# wl_phy_rx_11b_secure register map
Vendor: Texas Instruments
Peripheral module from a debugger description file (folder CC35X1E).
Registers are 32-bit, read-only, no defined reset value unless marked. A register's access mark holds for its fields unless they carry their own. Offsets are as the file gives them; lines under a group give offsets from that group; [hi:lo] are bit positions; {n}, {i} and the like mark numbered series; 'fields as' and 'values as' point back to an identical list; <NAME> marks a mode.

## wl_phy_rx_11b_secure
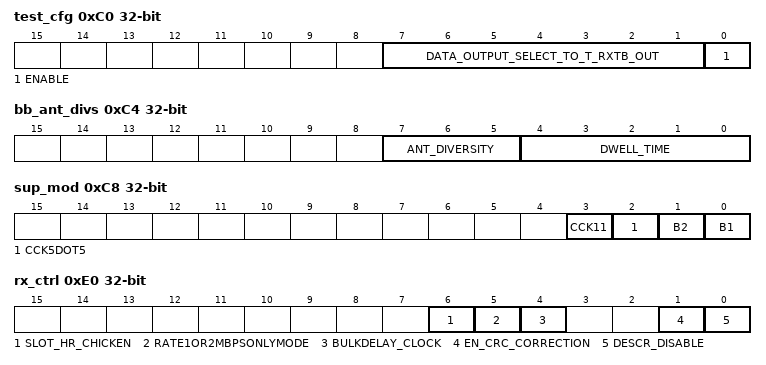
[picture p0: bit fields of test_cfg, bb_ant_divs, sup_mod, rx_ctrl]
0xC0 test_cfg access per field
  [7:1] DATA_OUTPUT_SELECT_TO_T_RXTB_OUT rw — Select data to output on t_rxtb_out
  [0] ENABLE rw — 0: disabled 1: output selected data on t_rxtb_out
0xC4 bb_ant_divs access per field — Antenna Diversity State Machine (BB_ANT_DIVS) (0x4bb1) In partial diversity, the antennas switch based on the dwell time. When barkerSync is valid at the end of a dwell time, the current antenna is declared as the one to use for the incoming packet. If the packet is later lost (or after it is completely received), the antenna switching (and searching for a new packet) will start again. In b-only full diversity, the antennas will switch based on dwell time until barkerSync is valid at the end of a dwell time. At that point the current antenna is declared the first antenna and the full diversity algorithm starts. The other full diversity modes are 11g compatible and do not switch antennas until after the rxtb block is granted control of the packet with the rxt_go_b signal. They allow control of the starting antenna when using full diversity - antenna 1 as we had in the past, and now new options to start on antenna 2 or the last antenna a packet was received on. MatanY - TODO - Can we move this register?
  [7:5] ANT_DIVERSITY rw — Ant_Diversity (802.11b-only mode, in which antennas are switched until an 11b acknowledgement. Set 0x2002 to 0x2 for 11b-only processing.) (802.11b-only mode, in which antennas are switched until an 11b acknowledgement. The last antenna selected is then used as the starting antenna for full diversity. Set 0x2002 to 0x2 for 11b-only processing.)Note: For full diversity modes, registers 0x4BD4, 0x4BD5, 0x4BD6, and 0x2003 must also be programmed.Note: Antenna1 and antenna2 refer to the RXANT0 and RXANT1 fields in register BB_ANT_SEL_CFG, respectively, which specify the actual mapping of radio control signals for antenna selection. 0x0: Antenna 1 fixed (never switch to antenna 2) (default) 0x1: Antenna 2 fixed (never switch to antenna 1) 0x2: Full Diversity, Antenna1-Start Mode 0x3: Partial Diversity 0x4: Full Diversity, Antenna2-Start Mode 0x5: Full Diversity, Last-RX-Antenna-Start Mode 0x6: Full Diversity, 802.11b-Only Mode
  [4:0] DWELL_TIME rw — Dwell_TimeDefines the antenna dwell time in micro seconds. This is the amount of time the TNETW1150 remains on an antenna when switching between antennas in one of the diversity modes. A dwell time of 0xA has been determined to be optimal for the TNETW1150. 00000 is a special case and will be interpreted as 00001.
0xC8 sup_mod access per field — This register specifies the supported modulation modes for 11b. The default specifies all available modulation modes. Specific modes are disabled by writing a "0" to the corresponding bit. If a packet is received with a modulation type that is disabled, it will be discarded, and RX_STAT[3] will be set to indicate an unsupported modulation error.
  [3] CCK11 rw — 11 Mbit/s CCK
  [2] CCK5DOT5 rw — 5.5 Mbit/s CCK
  [1] B2 rw — 2 Mbit/s Barker
  [0] B1 rw — 1 Mbit/s Barker
0xE0 rx_ctrl access per field
  [6] SLOT_HR_CHICKEN rw — This bit controls an RTL change that was made, which reduces the 11b Rx-listen current by ~350uA. The RTL change is not supposed to have any implication on performance. This bit stops the HRDemod_inputs_en from blocking the slot[2:0] signal to all the High-Rate modules. 0 - The power saving change is active (Default) 1 - No power savings. This mode better resembles the 1251 and 1273.
  [5] RATE1OR2MBPSONLYMODE rw — 0 - The 11b receiver is ready to receive DSSS and CCK packets (1,2,5.5,11 Mbps). (Default) 1 - The 11b receiver is ready to receive only DSSS packets (1,2 Mbps). This setting saves power by disabling the FFE and DFE adaptation during the 11b preamble. CCK packets will be classifed as unsupported by the PLCP.
  [4] BULKDELAY_CLOCK rw — This bit controls the CCK (HighRate) power saving mode. Power is reduced by turning the bulkDelay module on only when an 11b packet is detected. This reduces quiescent listen current by approximately 100uA. The bulkDelay clock is called hrbdClk80, and hrbdClk80_en controls it. 0 - The power reduction is active (Default). This setting introduces very small (and unnoticeable) performance degradation, due to the small reduction in FFE and DFE adaptation time. 1 - The power reduction is not active. bulkDelay is active all the time. This setting better resembles the 1271 and 1251.
  [1] EN_CRC_CORRECTION rw — when asserted this bit enables the crc 1-bit correction mechanism.
  [0] DESCR_DISABLE rw — De-scrambler DisableSetting this bit disables the internal de-scrambler. When this bit is cleared (default), the de-scrambler is enabled.
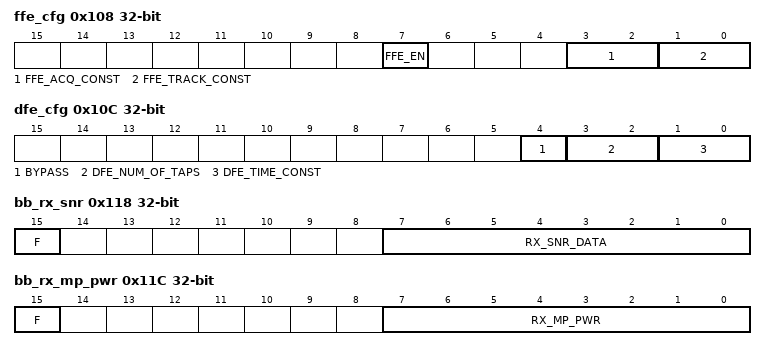
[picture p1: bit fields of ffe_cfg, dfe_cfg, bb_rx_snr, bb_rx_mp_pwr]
0x108 ffe_cfg access per field
  [7] FFE_EN rw — FFE_Enable Setting this bit enables the FFE during the payload portion of a packet. The FFE is always enabled (when the high rate demod is enabled) before the payload. The default is disabled during the payload.
  [3:2] FFE_ACQ_CONST rw — FFE Acquisition Time Constant
  [1:0] FFE_TRACK_CONST rw — FFE Tracking Time Constant
0x10C dfe_cfg access per field
  [4] BYPASS rw — Bypass DFE - When unset, DFE coefficients and FFE output are fed to the decoder. When set, zeros are fed to the decoder instead of the DFE coefficients, and the slicer inputs (FFE output + DFE output) are fed to the decoder instead of the FFE output.
  [3:2] DFE_NUM_OF_TAPS rw — DFE Number of Taps - Specifies the number of DFE Taps to use. 00 - Zero taps (DFE disabled) 01 - 2 taps 10 - 4 taps 11 - 8 taps
  [1:0] DFE_TIME_CONST rw — DFE Time Constant This Field contains the DFE time constant. Should write with the default value 0b01.
0x114 hr_input_dly access per field — This register is used to balance the delay paths from the low rate block to the high rate block. It should not be modified during normal operation. NOTE: Software that previously wrote to this register will cause problems. This register only used 3 bits before and that value was added to 0d28 to calculate the final offset. Now the full 6-bit offset needs to be written. NOTE1: Because of the design changes from Legolas to this RTL, this register has to be written a value which is three more than what it was for Legolas. For Example if a value of 6'h20 was being programmed for Legolas then for this RTL we need to program 6'h23.
  [5:0] HR_INPUT_DELAY rw — High-rate input delay to the FFE.
0x118 bb_rx_snr — This read-only register indicates the estimated noise power of the equalized receive signal at the input of the FEC decoder. The noise measurement becomes valid at the end of the PLCP header.
  [15] F — High for valid data
  [7:0] RX_SNR_DATA — Data
0x11C bb_rx_mp_pwr — This read-only register indicates the multipath power level, which is an estimated value proportional to the signal-to-ISI ratio observed on the received signal.
  [15] F — High for valid data
  [7:0] RX_MP_PWR — Data
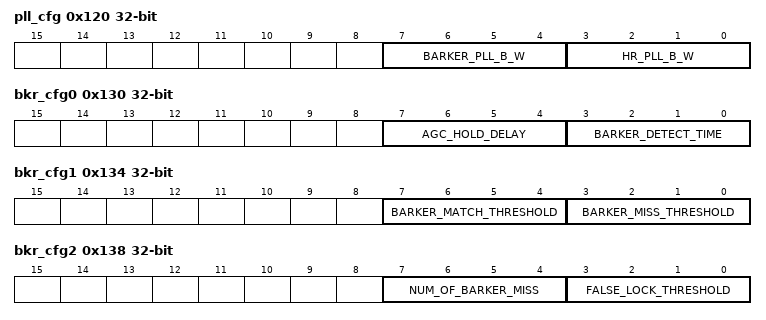
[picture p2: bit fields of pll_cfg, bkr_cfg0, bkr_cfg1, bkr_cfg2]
0x120 pll_cfg access per field
  [7:4] BARKER_PLL_B_W rw — Barker PLL Bandwidth 0000 - 201 kHz 0101 - 66 kHz 1010 - 30 kHz 1111 - 15 kHz (default)
  [3:0] HR_PLL_B_W rw — High-Rate PLL Bandwidth 0000 - 228 kHz 0101 - 113 kHz 1010 - 56 kHz 1111 - 28 kHz (default)
0x124 pll_init_cfg access per field
  [3:0] PLL_INIT_CONFIG rw — PLL Initialization Configuration - This field specifies the number of samples used by the PLL initialization module. The value of this field is an unsigned integer from 0 to 15.
0x130 bkr_cfg0 access per field
  [7:4] AGC_HOLD_DELAY rw — AGC Hold Delay. This field indicates the number of Barker symbols for which the analog AGC remains in short integration mode after the correlator obtains Barker Sync. See Section 3.6 AGC Notes on page 29 for more information on how the AGCs are controlled.
  [3:0] BARKER_DETECT_TIME rw — Barker Detect Time Constant. This field contains the Barker correlator detect time constant. It is recommended that you use the default value, 0b1110, when writing to this field. This field controls an accumulator that keeps a running power estimate. The individual bits for the feedback are explained below: 3 - Add 1/2 of old accum to new correlator power 2 - Add 1/4 of old accum to new correlator power 1 - Add 1/8 of old accum to new correlator power 0 - Add 1/16 of old accum to new correlator power
0x134 bkr_cfg1 access per field
  [7:4] BARKER_MATCH_THRESHOLD rw — Barker Match Threshold. This field specifies the number of matched correlations needed for the Barker correlator to establish synchronization.
  [3:0] BARKER_MISS_THRESHOLD rw — Barker Miss Threshold. This field specifies the number of missed correlations before the Barker correlators drops synchronization.
0x138 bkr_cfg2 access per field
  [7:4] NUM_OF_BARKER_MISS rw — Barker Miss in Search. This field specifies the number of missed correlations during Barker synchronization before the state machine is reset.
  [3:0] FALSE_LOCK_THRESHOLD rw — False Lock Threshold. This field contains the false lock threshold. It is recommended that you use the default value, 0x8, when writing to this field.
0x13C bkr_thresh0 access per field — This register contains the Barker correlator output threshold, which determines when to start the Barker synchronization state machine. BKR_THRESH1(0x4bdb) is a closely related register. Any change to BKR_THRESH register value would also require a change to BKR_THRESH1 register.
  [7:0] BARKER_CORRELATOR_OUTPUT_THRESHOLD rw
0x140 update_cfg_train access per field
  [4:2] FFE_UPDATE_PERIOD rw — Training Update Period. This field specifies the FFE update period during training (preamble and packet header) shown below: 000: Constant update 001: 2 symbols 010: 4 symbols 011: 6 symbols (default) 100: 8 symbols 101: 10 symbols 110: 12 symbols 111: 14 symbols
0x144 update_cfg_5 access per field
  [4:2] FFE_UPDATE_PERIOD rw — 5.5 Mbit/s Update Period. This field specifies the FFE update period for 5.5 Mbit/s packets as shown below 000: Constant update 001: 2 symbols 010: 4 symbols 011: 6 symbols 100: 8 symbols 101: 10 symbols 110: 12 symbols (default) 111: 14 symbols
0x148 update_cfg_11 access per field
  [4:2] FFE_UPDATE_PERIOD rw — 11 Mbit/s Update Period. This field specifies the FFE update period for 11 Mbit/s packets as shown below: 000: Constant update 001: 2 symbols 010: 4 symbols 011: 6 symbols (default) 100: 8 symbols 101: 10 symbols 110: 12 symbols 111: 14 symbols
0x150 strength_thresh access per field — See "Diversity Algorithm" section for more information on this register. MatanY - TODO - Can be removed?
  [7:0] STRENGTH_THRESHOLD rw — Barker Correlator Output Threshold
0x154 strength_range access per field — See "Diversity Algorithm" section for more information on this register. MatanY - TODO - Can be removed?
  [3:0] STRENGTH_RANGE rw
0x158 bias_corr_thresh access per field — See "Diversity Algorithm" section for more information on this register. MatanY - TODO - Can be removed?
  [7:0] BIAS_CORRELATION_THRESHOLD rw
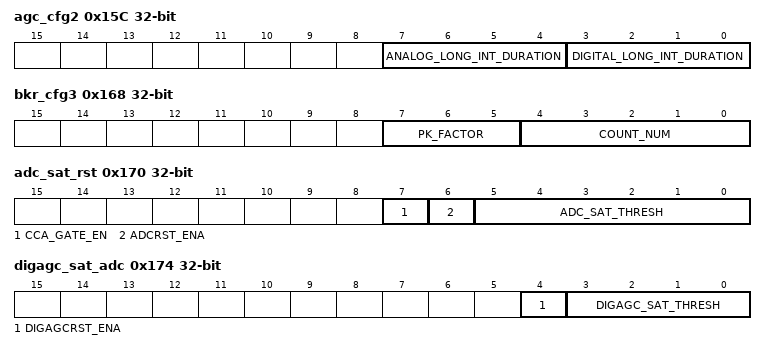
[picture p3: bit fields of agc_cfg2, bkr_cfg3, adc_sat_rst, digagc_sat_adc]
0x15C agc_cfg2 access per field — MatanY - TODO - Does AGC connected to this module?
  [7:4] ANALOG_LONG_INT_DURATION rw — Number of barker symbols to use for the analog AGC long integration mode. After barker sync (11b packet detection), this field sets the amount of time to allow for individual long integration periods of the analog AGC. When this time elapses, the analog AGC freezes and the digital AGC begins operation with long integration periods.
  [3:0] DIGITAL_LONG_INT_DURATION rw — Number of barker symbols to use for for the digital AGC long integration mode. After analog AGC freeze, this field sets the amount of time to allow for individual long integration periods of the digital AGC. When this time elapses, the digital AGC freezes for the rest of the packet.
0x164 evm_db_11b — This register contains the result of 11b EVM block. The value is in Two's complement and in decibel scale. The algorithm is different for low rate and high rate receivers in 11b so EVM of a low rate packet cannot be compared with EVM of a high rate packet. This register is updated at the end of a received packet. This register is also listed under the "EVM IP Block"/cgt.
  [7:0] ELEVEN_B_EVM — EVM_dB_11b
0x168 bkr_cfg3 access per field
  [7:5] PK_FACTOR rw — The scaling factor applied on pk_value to calculate tmp_pk_value. Default(010) means 1.25. Valid Range is 0 to 7. (8/8 to 15/8).
  [4:0] COUNT_NUM rw — The new tmp_pk_value calculated will be used for count (a signal in the DmodCorrSM) greater than this.If the value of count_num is greater than 21 the tmp_pk_value calculated wont be used.Typical value of count_num=17.
0x16C bkr_thresh1 access per field — The register corresponding to BKR_THRESH >>1. Now this need not be BKR_THRESH >>1. In fact the default value is same as BKR_THRESH. This change was made due to the change in agc behavior. This register was added for 1150/1251. To make the algorithm equivalent to that of 1140 program half the value that is being programmed to BKR_THRESH register 0x4BCF.
  [7:0] THRESHHOLDBY2 rw
0x170 adc_sat_rst access per field — ADC Saturation Reset
  [7] CCA_GATE_EN rw — When this bit is set the signal 'rxtb_cca' going out of rxtb module is gated with rxt_go_b signal coming from g state machine. That means when rxt_go_b is low, rxtb_cca always indicates clear channel.
  [6] ADCRST_ENA rw — Enable the option to reset the Barker State and correlators. By default this is disabled.
  [5:0] ADC_SAT_THRESH rw — If the number of saturations of analog 80 Mhz ADC (either I or Q) is more than adc_sat_thresh in a block of 40 samples (0.5us), the barker state machine and the 22 correlator power accumulators are reset. This is done only if bit 6 is high and the current Barker state is SEARCH or PRE_SYNC.
0x174 digagc_sat_adc access per field — Digital AGC Saturation Reset
  [4] DIGAGCRST_ENA rw — Enable the option to reset the Barker State and correlators. By default this is disabled.
  [3:0] DIGAGC_SAT_THRESH rw — If the number of saturations of 22Mhz 11b Digital AGC outputs (either I or Q) is more than digagc_sat_thresh in a block of 11 samples (0.5us), the barker state machine and the 22 correlator power accumulators are reset. This is done only if bit 4 is high and the current Barker state is SEARCH or PRE_SYNC.
0x178 pll_init_cfg2 access per field
  [4:0] ANT_DIVS2 rw — The dwell time in microseconds when antenna is in Check First. Programming this register with the same value as 0x4BB1[4:0] will make it backward compatible with Legolas PG1.1. When antenna diversity is FULL (i.e. 0x4BB1[7:5]=010) we don t have to dwell in first antenna for more than say 3-4 us after barker sync. So the preferred value of this is 0x04 when diversity is FULL. Otherwise this should be same as 0x4BB1[4:0]. MatanY - TODO - Can be removed?
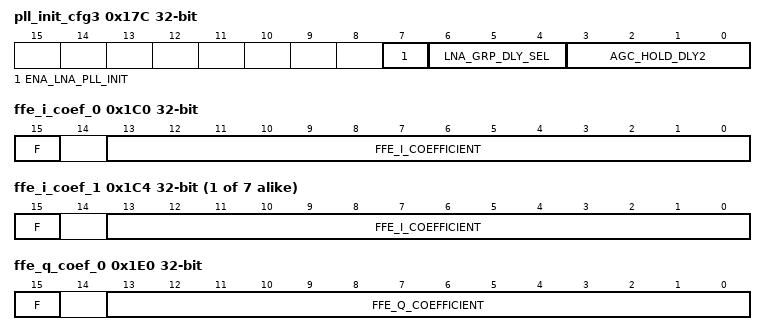
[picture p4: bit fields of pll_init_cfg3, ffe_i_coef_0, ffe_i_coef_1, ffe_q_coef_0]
0x17C pll_init_cfg3 access per field
  [7] ENA_LNA_PLL_INIT rw — ena_lna_pll_init. When 1 is written to this register the LNA FIX as described in Section 3.7will be enabled.(This will restart the PLL Initialization whenever the LNAs switch).
  [6:4] LNA_GRP_DLY_SEL rw — lna_grp_dly_sel. The select bits for the group delay as described in Section 3.7.This delay from LNA switch to start of PLL Initialization accounts for the delay from LNA/ADC op to LR PLL INIT module input. 0x0: max_cnt_us = 9'd20; //.25 us 0x1: max_cnt_us = 9'd100;//1.25us 0x2: max_cnt_us = 9'd120;//1.5us 0x3: max_cnt_us = 9'd140;//1.75us 0x4: max_cnt_us = 9'd160;//2us 0x5: max_cnt_us = 9'd180;//2.25us 0x6: max_cnt_us = 9'd200;//2.5us 0x7: max_cnt_us = 9'd220;//2.75us
  [3:0] AGC_HOLD_DLY2 rw — AGC_HOLD_DLY2. This field indicates the number of Barker symbols for which the analog AGC remains in short integration mode after the correlator obtains Barker Sync in antennas Check Second and Check Third. This Register is provided because the agc is already in short integration till barker Sync is obtained and since the barker detect delay is typically 7-8 us this extra dwelling need not be there. Programming this to zero will make the agc go from Short to Long Integration just after getting the Barker Sync. Programming AGC_HOLD_DLY2 to the same value as 0x4BCC[7:4] will make it backward compatible with Legolas PG1.1.The recommended value of AGC_HOLD_DLY2 is 0x0.
0x1C0 ffe_i_coef_0
  [15] F — High for valid data
  [13:0] FFE_I_COEFFICIENT
{0x1C0+4i} ffe_i_coef_{i} (i=1..7)
  [15] F, [13:0] FFE_I_COEFFICIENT
0x1E0 ffe_q_coef_0 — TODO - this register wasn't included in WL8 list, need to check if it is actually routed
  [15] F, [13:0] FFE_Q_COEFFICIENT
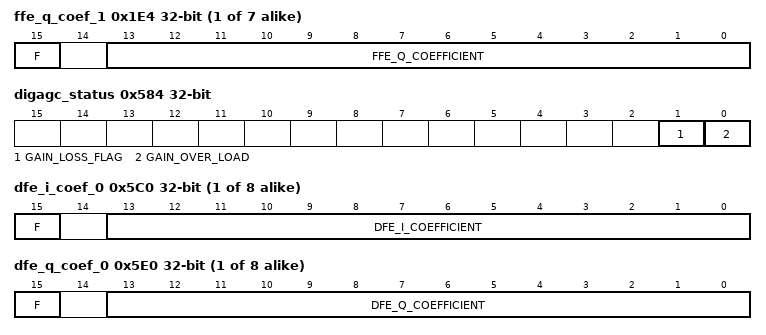
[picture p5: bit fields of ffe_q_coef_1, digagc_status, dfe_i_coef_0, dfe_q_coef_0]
{0x1E0+4i} ffe_q_coef_{i} (i=1..7)
  [15] F — High for valid data
  [13:0] FFE_Q_COEFFICIENT — ffe I coefficient
0x584 digagc_status — Digital AGC Status Register
  [1] GAIN_LOSS_FLAG — 0: gain loss flag is not set. 1: gain loss flag is set.
  [0] GAIN_OVER_LOAD — 0: gain over load flag is not set. 1: gain over load flag is set.
0x588 dyngain — Dynamic Gain Register
  [6:0] GAIN_VALUE — This read only register receives the gain value dynamically selected by the digital AGC module (output from the gain table), which would be required to set the level into the 11b core to an optimum value.
{0x5C0+4i} dfe_i_coef_{i} (i=0..7)
  [15] F — high for valid data
  [13:0] DFE_I_COEFFICIENT
{0x5E0+4i} dfe_q_coef_{i} (i=0..7)
  [15] F — high for valid data
  [13:0] DFE_Q_COEFFICIENT
